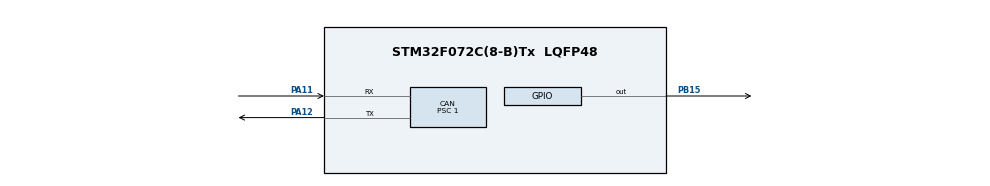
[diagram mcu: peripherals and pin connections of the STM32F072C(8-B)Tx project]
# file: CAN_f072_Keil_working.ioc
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CAN.BS1=CAN_BS1_13TQ
CAN.BS2=CAN_BS2_2TQ
CAN.CalculateBaudRate=500000
CAN.CalculateTimeBit=2000
CAN.CalculateTimeQuantum=125.0
CAN.Prescaler=1
Mcu.Family=STM32F0
Mcu.Name=STM32F072C(8-B)Tx
Mcu.Package=LQFP48
NVIC.CEC_CAN_IRQn=true\:0\:0\:false\:false\:true\:true\:true\:true
PA11.Mode=CAN_Activate
PA11.Signal=CAN_RX
PA12.Mode=CAN_Activate
PA12.Signal=CAN_TX
PA13.Mode=Serial_Wire
PA13.Signal=SYS_SWDIO
PA14.Mode=Serial_Wire
PA14.Signal=SYS_SWCLK
PB15.Signal=GPIO_Output
PF0-OSC_IN.Mode=HSE-External-Oscillator
PF0-OSC_IN.Signal=RCC_OSC_IN
PF1-OSC_OUT.Mode=HSE-External-Oscillator
PF1-OSC_OUT.Signal=RCC_OSC_OUT
ProjectManager.HeapSize=0x200
ProjectManager.StackSize=0x400
ProjectManager.TargetToolchain=STM32CubeIDE
board=custom

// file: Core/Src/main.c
/* USER CODE BEGIN Header */
/**
  ******************************************************************************
  * @file           : main.c
  * @brief          : Main program body
  ******************************************************************************
  * @attention
  *
  * Copyright (c) 2025 STMicroelectronics.
  * All rights reserved.
  *
  * This software is licensed under terms that can be found in the LICENSE file
  * in the root directory of this software component.
  * If no LICENSE file comes with this software, it is provided AS-IS.
  *
  ******************************************************************************
  */
/* USER CODE END Header */
#include "main.h"

/* USER CODE BEGIN Includes */
#include <string.h>
/* USER CODE END Includes */

/* USER CODE BEGIN PTD */
volatile uint8_t messageReceived = 0;
CAN_RxHeaderTypeDef rxHeader;
uint8_t rxData[8];
/* USER CODE END PTD */

CAN_HandleTypeDef hcan;

void SystemClock_Config(void);
static void MX_GPIO_Init(void);
static void MX_CAN_Init(void);
/* USER CODE BEGIN PFP */
void can_irq(CAN_HandleTypeDef *pcan);
HAL_StatusTypeDef can_send(uint32_t id, uint8_t data[], uint8_t length);
/* USER CODE END PFP */

/* USER CODE BEGIN 0 */
void can_irq(CAN_HandleTypeDef *pcan) {
  /* Simply receive whatever message comes in */
  if (HAL_CAN_GetRxMessage(pcan, CAN_RX_FIFO0, &rxHeader, rxData) == HAL_OK) {
    messageReceived = 1;
  }
}

HAL_StatusTypeDef can_send(uint32_t id, uint8_t data[], uint8_t length) {
  CAN_TxHeaderTypeDef txHeader;
  uint32_t mailbox;

  /* Configure TX header */
  txHeader.StdId = id;
  txHeader.IDE = CAN_ID_STD;
  txHeader.RTR = CAN_RTR_DATA;
  txHeader.DLC = length;
  txHeader.TransmitGlobalTime = DISABLE;

  /* Check if mailbox is available and send */
  if (HAL_CAN_GetTxMailboxesFreeLevel(&hcan) > 0) {
    return HAL_CAN_AddTxMessage(&hcan, &txHeader, data, &mailbox);
  }
  return HAL_BUSY;
}
/* USER CODE END 0 */

int main(void)
{

  /* USER CODE BEGIN 1 */
	uint8_t txData[] = "FuckCAN"; // Example data to send
  uint32_t lastSendTime = 0;
  /* USER CODE END 1 */

  /* MCU Configuration--------------------------------------------------------*/

  /* Reset of all peripherals, Initializes the Flash interface and the Systick. */
  HAL_Init();

  /* Configure the system clock */
  SystemClock_Config();

  /* Initialize all configured peripherals */
  MX_GPIO_Init();
  MX_CAN_Init();
  /* USER CODE BEGIN 2 */
	HAL_GPIO_WritePin(GPIOB, GPIO_PIN_15, GPIO_PIN_SET); // LED off
  /* USER CODE END 2 */

  /* Infinite loop */
  while (1)
  {

    /* USER CODE BEGIN 3 */
		/* Send message every 1000ms */

    if (HAL_GetTick() - lastSendTime > 1000) {
      if (can_send(0x123, txData, sizeof(txData)) == HAL_OK) {
        HAL_GPIO_TogglePin(GPIOB, GPIO_PIN_15); // Toggle LED on successful send
      }
      lastSendTime = HAL_GetTick();
    }

    /* If message received, toggle LED */

//    if (messageReceived) {
//      HAL_GPIO_TogglePin(GPIOB, GPIO_PIN_15);
//      messageReceived = 0; // Clear flag
//    }

		HAL_Delay(50);
  }
  /* USER CODE END 3 */
}

void SystemClock_Config(void)
{
  RCC_OscInitTypeDef RCC_OscInitStruct = {0};
  RCC_ClkInitTypeDef RCC_ClkInitStruct = {0};

  /** Initializes the RCC Oscillators according to the specified parameters
  * in the RCC_OscInitTypeDef structure.
  */
  RCC_OscInitStruct.OscillatorType = RCC_OSCILLATORTYPE_HSI;
  RCC_OscInitStruct.HSIState = RCC_HSI_ON;
  RCC_OscInitStruct.HSICalibrationValue = RCC_HSICALIBRATION_DEFAULT;
  RCC_OscInitStruct.PLL.PLLState = RCC_PLL_NONE;
  if (HAL_RCC_OscConfig(&RCC_OscInitStruct) != HAL_OK)
  {
    Error_Handler();
  }

  /** Initializes the CPU, AHB and APB buses clocks
  */
  RCC_ClkInitStruct.ClockType = RCC_CLOCKTYPE_HCLK|RCC_CLOCKTYPE_SYSCLK
                              |RCC_CLOCKTYPE_PCLK1;
  RCC_ClkInitStruct.SYSCLKSource = RCC_SYSCLKSOURCE_HSI;
  RCC_ClkInitStruct.AHBCLKDivider = RCC_SYSCLK_DIV1;
  RCC_ClkInitStruct.APB1CLKDivider = RCC_HCLK_DIV1;

  if (HAL_RCC_ClockConfig(&RCC_ClkInitStruct, FLASH_LATENCY_0) != HAL_OK)
  {
    Error_Handler();
  }
}

static void MX_CAN_Init(void)
{

  hcan.Instance = CAN;
  hcan.Init.Prescaler = 1;
  hcan.Init.Mode = CAN_MODE_NORMAL;
  hcan.Init.SyncJumpWidth = CAN_SJW_1TQ;
  hcan.Init.TimeSeg1 = CAN_BS1_13TQ;
  hcan.Init.TimeSeg2 = CAN_BS2_2TQ;
  hcan.Init.TimeTriggeredMode = DISABLE;
  hcan.Init.AutoBusOff = DISABLE;
  hcan.Init.AutoWakeUp = DISABLE;
  hcan.Init.AutoRetransmission = DISABLE;
  hcan.Init.ReceiveFifoLocked = DISABLE;
  hcan.Init.TransmitFifoPriority = DISABLE;
  if (HAL_CAN_Init(&hcan) != HAL_OK)
  {
    Error_Handler();
  }
  /* USER CODE BEGIN CAN_Init 2 */
	CAN_FilterTypeDef sf;
  sf.FilterMaskIdHigh = 0x0000;
  sf.FilterMaskIdLow = 0x0000;
  sf.FilterFIFOAssignment = CAN_FILTER_FIFO0;
  sf.FilterBank = 0;
  sf.FilterMode = CAN_FILTERMODE_IDMASK;
  sf.FilterScale = CAN_FILTERSCALE_32BIT;
  sf.FilterActivation = CAN_FILTER_ENABLE;
  if (HAL_CAN_ConfigFilter(&hcan, &sf) != HAL_OK) { Error_Handler(); }

  if (HAL_CAN_RegisterCallback(&hcan, HAL_CAN_RX_FIFO0_MSG_PENDING_CB_ID, can_irq) != HAL_OK) { Error_Handler(); }

  if (HAL_CAN_Start(&hcan) != HAL_OK) { Error_Handler(); }

  if (HAL_CAN_ActivateNotification(&hcan, CAN_IT_RX_FIFO0_MSG_PENDING) != HAL_OK) { Error_Handler(); }

  /* Enable interrupts for CAN: FIFO0 message pending, transmit mailbox empty, error */
__HAL_CAN_ENABLE_IT(&hcan,
                    CAN_IT_RX_FIFO0_MSG_PENDING | // RX FIFO0 message
                    CAN_IT_TX_MAILBOX_EMPTY    | // Transmit mailbox empty
                    CAN_IT_ERROR_WARNING       | // Error warning
                    CAN_IT_ERROR_PASSIVE       | // Error passive
                    CAN_IT_BUSOFF              | // Bus-off
                    CAN_IT_LAST_ERROR_CODE     | // Last error code
                    CAN_IT_ERROR               ); // General error

/* Configure NVIC for CAN interrupts */
HAL_NVIC_SetPriority(CEC_CAN_IRQn, 0, 0);
HAL_NVIC_EnableIRQ(CEC_CAN_IRQn);
  /* USER CODE END CAN_Init 2 */

}

static void MX_GPIO_Init(void)
{
  GPIO_InitTypeDef GPIO_InitStruct = {0};

  /* GPIO Ports Clock Enable */
  __HAL_RCC_GPIOF_CLK_ENABLE();
  __HAL_RCC_GPIOB_CLK_ENABLE();
  __HAL_RCC_GPIOA_CLK_ENABLE();

  /*Configure GPIO pin Output Level */
  HAL_GPIO_WritePin(GPIOB, GPIO_PIN_15, GPIO_PIN_RESET);

  /*Configure GPIO pin : PB15 */
  GPIO_InitStruct.Pin = GPIO_PIN_15;
  GPIO_InitStruct.Mode = GPIO_MODE_OUTPUT_PP;
  GPIO_InitStruct.Pull = GPIO_NOPULL;
  GPIO_InitStruct.Speed = GPIO_SPEED_FREQ_LOW;
  HAL_GPIO_Init(GPIOB, &GPIO_InitStruct);

}

void Error_Handler(void)
{
  __disable_irq();
  while (1)
  {
  }
}
